# S32K116 register map
Vendor: NXP; Series: S32K; File version: 1.6
CPU: CM0PLUS r0p0, little endian, MPU, FPU, 2 interrupt priority bits
Registers are 32-bit, read-write, reset 0x0 unless marked. A register's access mark holds for its fields unless they carry their own. Offsets are from the block's base; [hi:lo] are bit positions; {n}, {i} and the like mark numbered series.

## CMU_FC_0 — CMU_FC
Base 0x4003E000; register names take the prefix CMU_FC_0_
0x00 GCR — CMU Frequency Check Global Configuration Register
  [0] FCE — Frequency Check Enable
    0=Frequency Check Disabled; 1=Frequency Check Enabled
0x04 RCCR — CMU Frequency Check Reference Count Configuration Register
  [15:0] REF_CNT — Reference Clock Count
0x08 HTCR reset 0xFFFFFF — CMU Frequency Check High Threshold Configuration Register
  [23:0] HFREF — High Frequency Reference Threshold
0x0C LTCR — CMU Frequency Check Low Threshold Configuration Register
  [23:0] LFREF — Low Frequency Reference Threshold
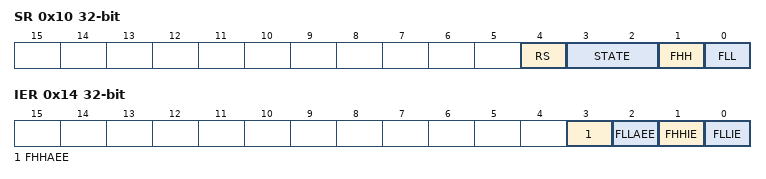
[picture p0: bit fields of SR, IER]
0x10 SR — CMU Frequency Check Status Register
  [4] RS ro — Run Status
    0=Frequency Check Stopped; 1=Frequency Check Running
  [3:2] STATE ro — Module State
    0=Configure State- Configuration registers and CMU_FC_IER programming is getting done; 1=Initialization State- Register configurations are getting loaded internally; 2=Initialization Wait State- The module stays in this state for 1 bus clock cycle; 3=Frequency Check State- The module is ready to start frequency check operation in this state
  [1] FHH — Frequency Higher than High Frequency Reference Threshold Event Status
    0=No FHH Event; 1=FHH Event Occured
  [0] FLL — Frequency Lower than Low Frequency Reference Threshold Event Status
    0=No FLL Event; 1=FLL Event Occured
0x14 IER — CMU Frequency Check Interrupt/Event Enable Register
  [3] FHHAEE — Frequency Higher than High Frequency Reference Threshold Asynchronous Event Enable
    0=Asynchronous FHH Event is Disabled; 1=Asynchronous FHH Event is Enabled
  [2] FLLAEE — Frequency Lower than Low Frequency Reference Threshold Asynchronous Event Enable
    0=Asynchronous FLL Event is Disabled; 1=Asynchronous FLL Event is Enabled
  [1] FHHIE — Frequency Higher than High Frequency Reference Threshold Interrupt Enable
    0=FHH Interrupt is Disabled; 1=FHH Interrupt is Enabled
  [0] FLLIE — Frequency Lower than Low Frequency Reference Threshold Interrupt Enable
    0=FLL Interrupt is Disabled; 1=FLL Interrupt is Enabled

## CMU_FC_1 — CMU_FC
Base 0x4003F000; register names take the prefix CMU_FC_1_
Registers as CMU_FC_0.

## LPTMR0 — Low Power Timer
Base 0x40040000; register names take the prefix LPTMR0_
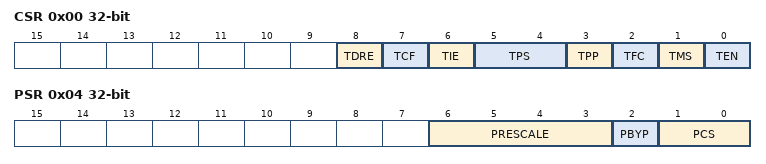
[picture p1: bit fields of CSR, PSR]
0x00 CSR — Low Power Timer Control Status Register
  [8] TDRE — Timer DMA Request Enable
    0=Timer DMA Request disabled; 1=Timer DMA Request enabled
  [7] TCF — Timer Compare Flag
    0=The value of CNR is not equal to CMR and increments; 1=The value of CNR is equal to CMR and increments
  [6] TIE — Timer Interrupt Enable
    0=Timer interrupt disabled; 1=Timer interrupt enabled
  [5:4] TPS — Timer Pin Select
    {v}=Pulse counter input {v} is selected (v=0..3)
  [3] TPP — Timer Pin Polarity
    0=Pulse Counter input source is active-high, and the CNR will increment on the rising-edge; 1=Pulse Counter input source is active-low, and the CNR will increment on the falling-edge
  [2] TFC — Timer Free-Running Counter
    0=CNR is reset whenever TCF is set; 1=CNR is reset on overflow
  [1] TMS — Timer Mode Select
    0=Time Counter mode; 1=Pulse Counter mode
  [0] TEN — Timer Enable
    0=LPTMR is disabled and internal logic is reset; 1=LPTMR is enabled
0x04 PSR — Low Power Timer Prescale Register
  [6:3] PRESCALE — Prescale Value
    0=Prescaler divides the prescaler clock by 2; glitch filter does not support this configuration; 1=Prescaler divides the prescaler clock by 4; glitch filter recognizes change on input pin after 2 rising clock edges; 2=Prescaler divides the prescaler clock by 8; glitch filter recognizes change on input pin after 4 rising clock edges; 3=Prescaler divides the prescaler clock by 16; glitch filter recognizes change on input pin after 8 rising clock edges; 4=Prescaler divides the prescaler clock by 32; glitch filter recognizes change on input pin after 16 rising clock edges; 5=Prescaler divides the prescaler clock by 64; glitch filter recognizes change on input pin after 32 rising clock edges; 6=Prescaler divides the prescaler clock by 128; glitch filter recognizes change on input pin after 64 rising clock edges; 7=Prescaler divides the prescaler clock by 256; glitch filter recognizes change on input pin after 128 rising clock edges; 8=Prescaler divides the prescaler clock by 512; glitch filter recognizes change on input pin after 256 rising clock edges; 9=Prescaler divides the prescaler clock by 1024; glitch filter recognizes change on input pin after 512 rising clock edges; 10=Prescaler divides the prescaler clock by 2048; glitch filter recognizes change on input pin after 1024 rising clock edges; 11=Prescaler divides the prescaler clock by 4096; glitch filter recognizes change on input pin after 2048 rising clock edges; 12=Prescaler divides the prescaler clock by 8192; glitch filter recognizes change on input pin after 4096 rising clock edges; 13=Prescaler divides the prescaler clock by 16,384; glitch filter recognizes change on input pin after 8192 rising clock edges; 14=Prescaler divides the prescaler clock by 32,768; glitch filter recognizes change on input pin after 16,384 rising clock edges; 15=Prescaler divides the prescaler clock by 65,536; glitch filter recognizes change on input pin after 32,768 rising clock edges
  [2] PBYP — Prescaler Bypass
    0=Prescaler/glitch filter is enabled; 1=Prescaler/glitch filter is bypassed
  [1:0] PCS — Prescaler Clock Select
    {v}=Prescaler/glitch filter clock {v} selected (v=0..3)
0x08 CMR — Low Power Timer Compare Register
  [15:0] COMPARE — Compare Value
0x0C CNR — Low Power Timer Counter Register
  [15:0] COUNTER — Counter Value
